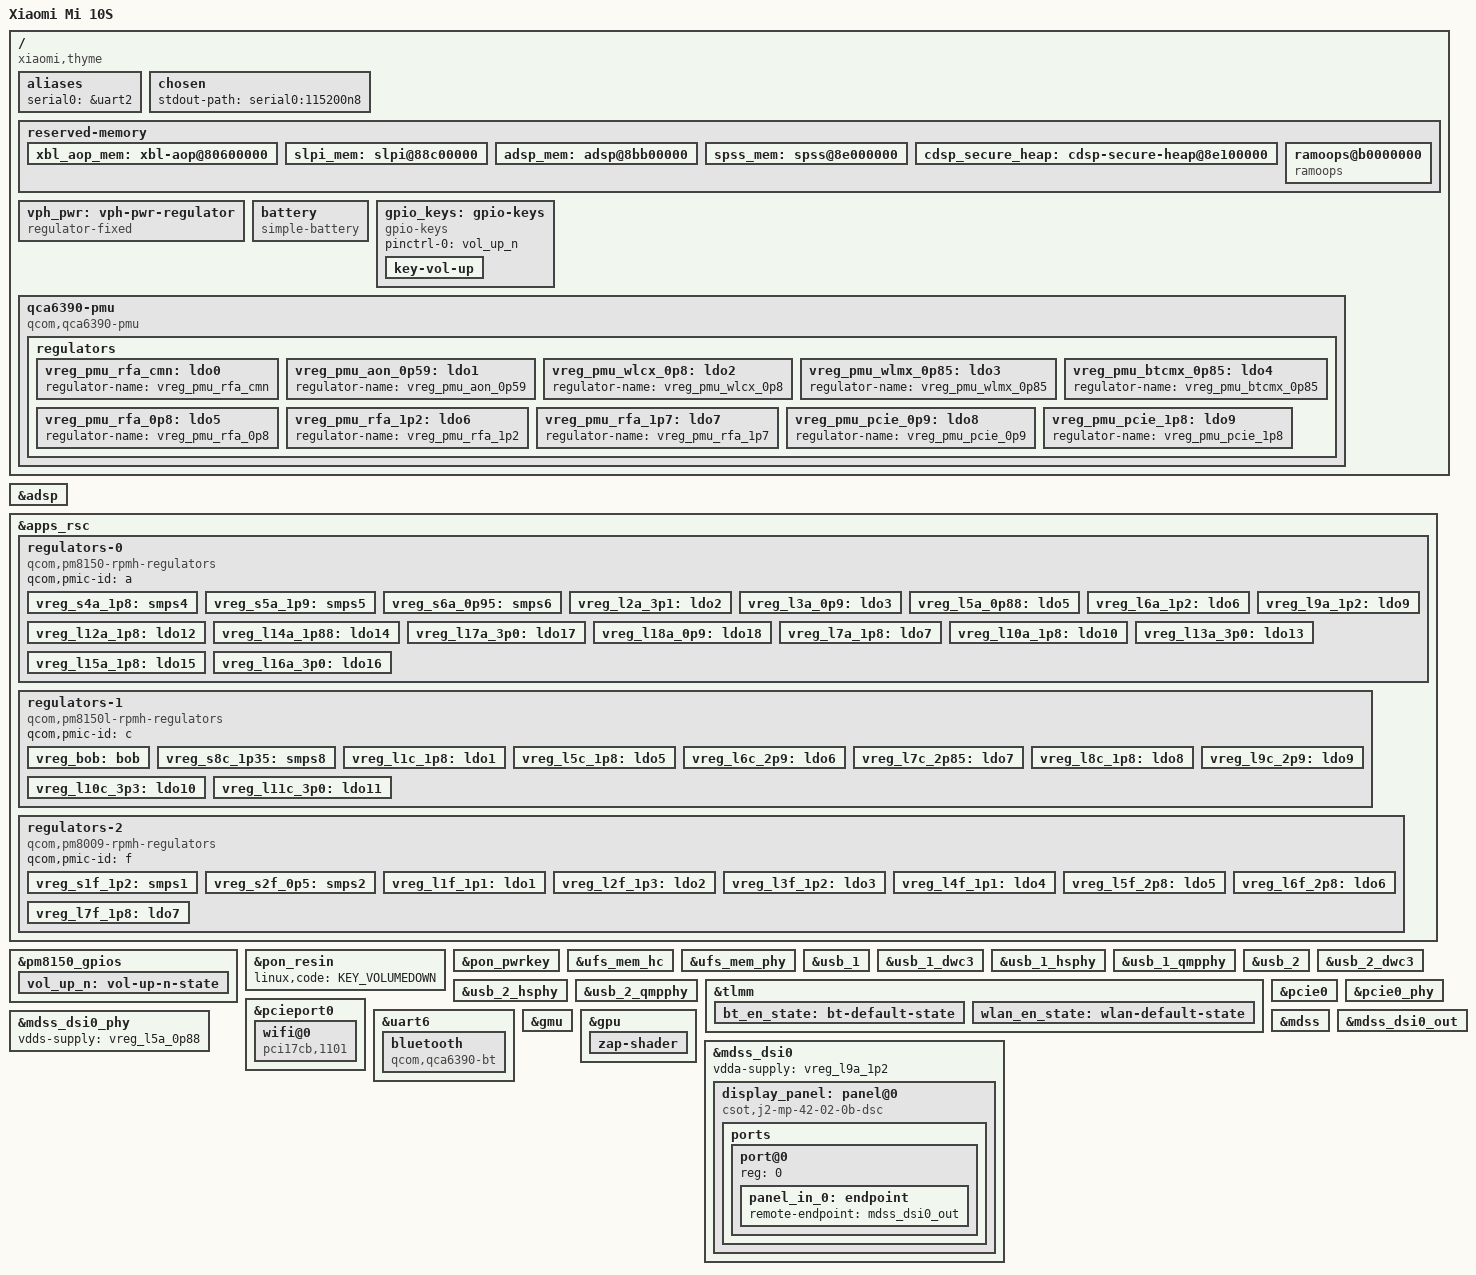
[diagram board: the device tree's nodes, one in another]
// SPDX-License-Identifier: BSD-3-Clause
/*
 * Xiaomi Mi 10S (thyme) — SM8250 (Kona v2.1)
 *
 * 基于 Linux 6.13 sm8250 平台骨架，独立构建。
 * 硬件事实来源：官方 4.19.157-perf 反编译树 dts-reference/thyme-official-full.dts。
 * 组织方式参照 sm8250-xiaomi-elish-common.dtsi（同为 Xiaomi SM8250）。
 *
 * 首批迁移：基础平台 / reserved-memory / PMIC / UFS / USB / 基础 GPIO。
 * 后续批次：PCIe(Wi-Fi/BT) / DPU·DSI / GPU / Audio / Touch / Charging / Sensors。
 */

/dts-v1/;

#include <dt-bindings/arm/qcom,ids.h>
#include <dt-bindings/gpio/gpio.h>
#include <dt-bindings/input/input.h>
#include <dt-bindings/leds/common.h>
#include <dt-bindings/phy/phy.h>
#include <dt-bindings/regulator/qcom,rpmh-regulator.h>
#include <dt-bindings/usb/pd.h>
#include "sm8250.dtsi"
#include "pm8150.dtsi"
#include "pm8150b.dtsi"
#include "pm8150l.dtsi"
#include "pm8009.dtsi"

/*
 * thyme 与 elish 同为 Xiaomi SM8250，reserved-memory 布局一致，
 * 且均与上游 sm8250.dtsi 默认值不同，故删除后按官方 4.19 值重定义。
 */
/delete-node/ &adsp_mem;
/delete-node/ &cdsp_secure_heap;
/delete-node/ &slpi_mem;
/delete-node/ &spss_mem;
/delete-node/ &xbl_aop_mem;

/ {
	model = "Xiaomi Mi 10S";
	compatible = "xiaomi,thyme", "qcom,sm8250";
	chassis-type = "handset";

	/* bootloader 选板依据（官方 4.19：msm-id 0x164/board-id 0x2d） */
	qcom,msm-id = <QCOM_ID_SM8250 0x20001>; /* SM8250 v2.1 */
	qcom,board-id = <45 0>;

	aliases {
		serial0 = &uart2;
	};

	chosen {
		stdout-path = "serial0:115200n8";
	};

	/*
	 * 内存布局由 bootloader 运行时填充（官方 4.19 静态 reg 为占位 0，
	 * 6.13 sm8250.dtsi 默认 memory@80000000 同样 size=0，由 BL 填 size）。
	 * 故不在此声明 memory，直接继承 6.13 基座的 bootloader-fill 语义。
	 */

	reserved-memory {
		xbl_aop_mem: xbl-aop@80600000 {
			reg = <0x0 0x80600000 0x0 0x260000>;
			no-map;
		};

		slpi_mem: slpi@88c00000 {
			reg = <0x0 0x88c00000 0x0 0x2f00000>;
			no-map;
		};

		adsp_mem: adsp@8bb00000 {
			reg = <0x0 0x8bb00000 0x0 0x2500000>;
			no-map;
		};

		spss_mem: spss@8e000000 {
			reg = <0x0 0x8e000000 0x0 0x100000>;
			no-map;
		};

		cdsp_secure_heap: cdsp-secure-heap@8e100000 {
			reg = <0x0 0x8e100000 0x0 0x4600000>;
			no-map;
		};

		ramoops@b0000000 {
			compatible = "ramoops";
			reg = <0x0 0xb0000000 0x0 0x400000>;
			record-size = <0x1000>;
			console-size = <0x200000>;
			ecc-size = <16>;
			no-map;
		};
	};

	vph_pwr: vph-pwr-regulator {
		compatible = "regulator-fixed";
		regulator-name = "vph_pwr";
		regulator-min-microvolt = <3700000>;
		regulator-max-microvolt = <3700000>;
	};

	/*
	 * 官方 4.19 throma j2nvtbm4n/j2gybm4n，4780mAh 双电芯六针。
	 * 电量计为高通 fg-gen4（6.13 无 driver），Capacity 值先落 simple-battery。
	 */
	battery: battery {
		compatible = "simple-battery";
		charge-full-design-microamp-hours = <4780000>;
		voltage-min-design-microvolt = <3870000>;
		energy-full-design-microwatt-hours = <18400000>;
	};

	gpio_keys: gpio-keys {
		compatible = "gpio-keys";

		pinctrl-names = "default";
		pinctrl-0 = <&vol_up_n>;

		key-vol-up {
			label = "Volume Up";
			gpios = <&pm8150_gpios 6 GPIO_ACTIVE_LOW>;
			linux,code = <KEY_VOLUMEUP>;
			debounce-interval = <15>;
			linux,can-disable;
			wakeup-source;
		};
	};

	/*
	 * QCA6390 Wi-Fi/Bluetooth 电源管理单元。
	 * 官方 4.19 cnss 五路供电(aon/dig/io/rfa1/rfa2) 在此改为 mainline pmu binding。
	 */
	qca6390-pmu {
		compatible = "qcom,qca6390-pmu";

		pinctrl-names = "default";
		pinctrl-0 = <&bt_en_state>, <&wlan_en_state>;

		vddaon-supply = <&vreg_s6a_0p95>;
		vddpmu-supply = <&vreg_s6a_0p95>;
		vddrfa0p95-supply = <&vreg_s6a_0p95>;
		vddrfa1p3-supply = <&vreg_s8c_1p35>;
		vddrfa1p9-supply = <&vreg_s5a_1p9>;
		vddpcie1p3-supply = <&vreg_s8c_1p35>;
		vddpcie1p9-supply = <&vreg_s5a_1p9>;
		vddio-supply = <&vreg_s4a_1p8>;

		wlan-enable-gpios = <&tlmm 20 GPIO_ACTIVE_HIGH>;
		bt-enable-gpios = <&tlmm 21 GPIO_ACTIVE_HIGH>;

		regulators {
			vreg_pmu_rfa_cmn: ldo0 {
				regulator-name = "vreg_pmu_rfa_cmn";
			};

			vreg_pmu_aon_0p59: ldo1 {
				regulator-name = "vreg_pmu_aon_0p59";
			};

			vreg_pmu_wlcx_0p8: ldo2 {
				regulator-name = "vreg_pmu_wlcx_0p8";
			};

			vreg_pmu_wlmx_0p85: ldo3 {
				regulator-name = "vreg_pmu_wlmx_0p85";
			};

			vreg_pmu_btcmx_0p85: ldo4 {
				regulator-name = "vreg_pmu_btcmx_0p85";
			};

			vreg_pmu_rfa_0p8: ldo5 {
				regulator-name = "vreg_pmu_rfa_0p8";
			};

			vreg_pmu_rfa_1p2: ldo6 {
				regulator-name = "vreg_pmu_rfa_1p2";
			};

			vreg_pmu_rfa_1p7: ldo7 {
				regulator-name = "vreg_pmu_rfa_1p7";
			};

			vreg_pmu_pcie_0p9: ldo8 {
				regulator-name = "vreg_pmu_pcie_0p9";
			};

			vreg_pmu_pcie_1p8: ldo9 {
				regulator-name = "vreg_pmu_pcie_1p8";
			};
		};
	};
};

&adsp {
	status = "okay";
	firmware-name = "qcom/sm8250/xiaomi/thyme/adsp.mbn";
};

&apps_rsc {
	regulators-0 {
		compatible = "qcom,pm8150-rpmh-regulators";
		qcom,pmic-id = "a";

		vreg_s4a_1p8: smps4 {
			regulator-name = "vreg_s4a_1p8";
			regulator-min-microvolt = <1800000>;
			regulator-max-microvolt = <1920000>;
			regulator-initial-mode = <RPMH_REGULATOR_MODE_HPM>;
		};

		vreg_s5a_1p9: smps5 {
			regulator-name = "vreg_s5a_1p9";
			regulator-min-microvolt = <1824000>;
			regulator-max-microvolt = <2040000>;
			regulator-initial-mode = <RPMH_REGULATOR_MODE_HPM>;
		};

		vreg_s6a_0p95: smps6 {
			regulator-name = "vreg_s6a_0p95";
			regulator-min-microvolt = <600000>;
			regulator-max-microvolt = <1128000>;
			regulator-initial-mode = <RPMH_REGULATOR_MODE_HPM>;
		};

		vreg_l2a_3p1: ldo2 {
			regulator-name = "vreg_l2a_3p1";
			regulator-min-microvolt = <3072000>;
			regulator-max-microvolt = <3072000>;
			regulator-initial-mode = <RPMH_REGULATOR_MODE_HPM>;
		};

		vreg_l3a_0p9: ldo3 {
			regulator-name = "vreg_l3a_0p9";
			regulator-min-microvolt = <928000>;
			regulator-max-microvolt = <932000>;
			regulator-initial-mode = <RPMH_REGULATOR_MODE_HPM>;
		};

		vreg_l5a_0p88: ldo5 {
			regulator-name = "vreg_l5a_0p88";
			regulator-min-microvolt = <880000>;
			regulator-max-microvolt = <880000>;
			regulator-initial-mode = <RPMH_REGULATOR_MODE_HPM>;
		};

		vreg_l6a_1p2: ldo6 {
			regulator-name = "vreg_l6a_1p2";
			regulator-min-microvolt = <1200000>;
			regulator-max-microvolt = <1200000>;
			regulator-initial-mode = <RPMH_REGULATOR_MODE_HPM>;
		};

		vreg_l9a_1p2: ldo9 {
			regulator-name = "vreg_l9a_1p2";
			regulator-min-microvolt = <1200000>;
			regulator-max-microvolt = <1200000>;
			regulator-initial-mode = <RPMH_REGULATOR_MODE_HPM>;
		};

		vreg_l12a_1p8: ldo12 {
			regulator-name = "vreg_l12a_1p8";
			regulator-min-microvolt = <1800000>;
			regulator-max-microvolt = <1800000>;
			regulator-initial-mode = <RPMH_REGULATOR_MODE_HPM>;
		};

		vreg_l14a_1p88: ldo14 {
			regulator-name = "vreg_l14a_1p88";
			regulator-min-microvolt = <1800000>;
			regulator-max-microvolt = <1880000>;
			regulator-initial-mode = <RPMH_REGULATOR_MODE_HPM>;
		};

		vreg_l17a_3p0: ldo17 {
			regulator-name = "vreg_l17a_3p0";
			regulator-min-microvolt = <2496000>;
			regulator-max-microvolt = <3008000>;
			regulator-initial-mode = <RPMH_REGULATOR_MODE_HPM>;
		};

		vreg_l18a_0p9: ldo18 {
			regulator-name = "vreg_l18a_0p9";
			regulator-min-microvolt = <912000>;
			regulator-max-microvolt = <912000>;
			regulator-initial-mode = <RPMH_REGULATOR_MODE_HPM>;
		};

		vreg_l7a_1p8: ldo7 {
			regulator-name = "vreg_l7a_1p8";
			regulator-min-microvolt = <1704000>;
			regulator-max-microvolt = <1800000>;
			regulator-initial-mode = <RPMH_REGULATOR_MODE_HPM>;
		};

		vreg_l10a_1p8: ldo10 {
			regulator-name = "vreg_l10a_1p8";
			regulator-min-microvolt = <1800000>;
			regulator-max-microvolt = <2960000>;
			regulator-initial-mode = <RPMH_REGULATOR_MODE_HPM>;
		};

		vreg_l13a_3p0: ldo13 {
			regulator-name = "vreg_l13a_3p0";
			regulator-min-microvolt = <3008000>;
			regulator-max-microvolt = <3008000>;
			regulator-initial-mode = <RPMH_REGULATOR_MODE_HPM>;
		};

		vreg_l15a_1p8: ldo15 {
			regulator-name = "vreg_l15a_1p8";
			regulator-min-microvolt = <1800000>;
			regulator-max-microvolt = <1800000>;
			regulator-initial-mode = <RPMH_REGULATOR_MODE_HPM>;
		};

		vreg_l16a_3p0: ldo16 {
			regulator-name = "vreg_l16a_3p0";
			regulator-min-microvolt = <3024000>;
			regulator-max-microvolt = <3304000>;
			regulator-initial-mode = <RPMH_REGULATOR_MODE_HPM>;
		};
	};

	regulators-1 {
		compatible = "qcom,pm8150l-rpmh-regulators";
		qcom,pmic-id = "c";

		vreg_bob: bob {
			regulator-name = "vreg_bob";
			regulator-min-microvolt = <3008000>;
			regulator-max-microvolt = <3960000>;
			regulator-initial-mode = <RPMH_REGULATOR_MODE_AUTO>;
		};

		vreg_s8c_1p35: smps8 {
			regulator-name = "vreg_s8c_1p35";
			regulator-min-microvolt = <1200000>;
			regulator-max-microvolt = <1400000>;
			regulator-initial-mode = <RPMH_REGULATOR_MODE_HPM>;
		};

		vreg_l1c_1p8: ldo1 {
			regulator-name = "vreg_l1c_1p8";
			regulator-min-microvolt = <1800000>;
			regulator-max-microvolt = <1800000>;
			regulator-initial-mode = <RPMH_REGULATOR_MODE_HPM>;
		};

		vreg_l5c_1p8: ldo5 {
			regulator-name = "vreg_l5c_1p8";
			regulator-min-microvolt = <1800000>;
			regulator-max-microvolt = <2800000>;
			regulator-initial-mode = <RPMH_REGULATOR_MODE_HPM>;
		};

		vreg_l6c_2p9: ldo6 {
			regulator-name = "vreg_l6c_2p9";
			regulator-min-microvolt = <1800000>;
			regulator-max-microvolt = <2960000>;
			regulator-initial-mode = <RPMH_REGULATOR_MODE_HPM>;
		};

		vreg_l7c_2p85: ldo7 {
			regulator-name = "vreg_l7c_2p85";
			regulator-min-microvolt = <2856000>;
			regulator-max-microvolt = <3104000>;
			regulator-initial-mode = <RPMH_REGULATOR_MODE_HPM>;
		};

		vreg_l8c_1p8: ldo8 {
			regulator-name = "vreg_l8c_1p8";
			regulator-min-microvolt = <1800000>;
			regulator-max-microvolt = <1800000>;
			regulator-initial-mode = <RPMH_REGULATOR_MODE_HPM>;
		};

		vreg_l9c_2p9: ldo9 {
			regulator-name = "vreg_l9c_2p9";
			regulator-min-microvolt = <2704000>;
			regulator-max-microvolt = <2960000>;
			regulator-initial-mode = <RPMH_REGULATOR_MODE_HPM>;
		};

		vreg_l10c_3p3: ldo10 {
			regulator-name = "vreg_l10c_3p3";
			regulator-min-microvolt = <3000000>;
			regulator-max-microvolt = <3312000>;
			regulator-initial-mode = <RPMH_REGULATOR_MODE_HPM>;
		};

		vreg_l11c_3p0: ldo11 {
			regulator-name = "vreg_l11c_3p0";
			regulator-min-microvolt = <3000000>;
			regulator-max-microvolt = <3312000>;
			regulator-initial-mode = <RPMH_REGULATOR_MODE_HPM>;
		};
	};

	regulators-2 {
		compatible = "qcom,pm8009-rpmh-regulators";
		qcom,pmic-id = "f";

		vreg_s1f_1p2: smps1 {
			regulator-name = "vreg_s1f_1p2";
			regulator-min-microvolt = <1200000>;
			regulator-max-microvolt = <1300000>;
			regulator-initial-mode = <RPMH_REGULATOR_MODE_HPM>;
		};

		vreg_s2f_0p5: smps2 {
			regulator-name = "vreg_s2f_0p5";
			regulator-min-microvolt = <512000>;
			regulator-max-microvolt = <1100000>;
			regulator-initial-mode = <RPMH_REGULATOR_MODE_HPM>;
		};

		vreg_l1f_1p1: ldo1 {
			regulator-name = "vreg_l1f_1p1";
			regulator-min-microvolt = <1104000>;
			regulator-max-microvolt = <1104000>;
			regulator-initial-mode = <RPMH_REGULATOR_MODE_HPM>;
		};

		vreg_l2f_1p3: ldo2 {
			regulator-name = "vreg_l2f_1p3";
			regulator-min-microvolt = <1056000>;
			regulator-max-microvolt = <1200000>;
			regulator-initial-mode = <RPMH_REGULATOR_MODE_HPM>;
		};

		vreg_l3f_1p2: ldo3 {
			regulator-name = "vreg_l3f_1p2";
			regulator-min-microvolt = <1056000>;
			regulator-max-microvolt = <1200000>;
			regulator-initial-mode = <RPMH_REGULATOR_MODE_HPM>;
		};

		vreg_l4f_1p1: ldo4 {
			regulator-name = "vreg_l4f_1p1";
			regulator-min-microvolt = <1104000>;
			regulator-max-microvolt = <1104000>;
			regulator-initial-mode = <RPMH_REGULATOR_MODE_HPM>;
		};

		vreg_l5f_2p8: ldo5 {
			regulator-name = "vreg_l5f_2p8";
			regulator-min-microvolt = <2800000>;
			regulator-max-microvolt = <3000000>;
			regulator-initial-mode = <RPMH_REGULATOR_MODE_HPM>;
		};

		vreg_l6f_2p8: ldo6 {
			regulator-name = "vreg_l6f_2p8";
			regulator-min-microvolt = <2800000>;
			regulator-max-microvolt = <3000000>;
			regulator-initial-mode = <RPMH_REGULATOR_MODE_HPM>;
		};

		vreg_l7f_1p8: ldo7 {
			regulator-name = "vreg_l7f_1p8";
			regulator-min-microvolt = <1800000>;
			regulator-max-microvolt = <1800000>;
			regulator-initial-mode = <RPMH_REGULATOR_MODE_HPM>;
		};
	};
};

&pm8150_gpios {
	vol_up_n: vol-up-n-state {
		pins = "gpio6";
		function = "normal";
		input-enable;
		bias-pull-up;
		power-source = <1>;
	};
};

&pon_resin {
	status = "okay";
	linux,code = <KEY_VOLUMEDOWN>;
};

&pon_pwrkey {
	status = "okay";
};

&ufs_mem_hc {
	vcc-supply = <&vreg_l17a_3p0>;
	vcc-max-microamp = <800000>;
	vccq-supply = <&vreg_l6a_1p2>;
	vccq-max-microamp = <800000>;
	vccq2-supply = <&vreg_s4a_1p8>;
	vccq2-max-microamp = <800000>;
	status = "okay";
};

&ufs_mem_phy {
	vdda-phy-supply = <&vreg_l5a_0p88>;
	vdda-pll-supply = <&vreg_l9a_1p2>;
	status = "okay";
};

&usb_1 {
	status = "okay";
};

&usb_1_dwc3 {
	dr_mode = "otg";
	/* 官方 4.19 thyme usb0 = USB 2.0 only */
	maximum-speed = "high-speed";
	phys = <&usb_1_hsphy>;
	phy-names = "usb2-phy";
};

&usb_1_hsphy {
	status = "okay";

	vdda-pll-supply = <&vreg_l5a_0p88>;
	vdda33-supply = <&vreg_l2a_3p1>;
	vdda18-supply = <&vreg_l12a_1p8>;
};

/* usb_1_qmpphy（combo DP phy）供 DP 视频输出，USB 数据仍走 HS */
&usb_1_qmpphy {
	status = "okay";

	vdda-phy-supply = <&vreg_l9a_1p2>;
	vdda-pll-supply = <&vreg_l18a_0p9>;
};

&usb_2 {
	status = "okay";
};

&usb_2_dwc3 {
	dr_mode = "host";
	/* 官方 4.19 thyme usb1 = USB 3.0 super-speed */
	maximum-speed = "super-speed";
};

&usb_2_hsphy {
	status = "okay";

	vdda-pll-supply = <&vreg_l5a_0p88>;
	vdda33-supply = <&vreg_l2a_3p1>;
	vdda18-supply = <&vreg_l12a_1p8>;
};

&usb_2_qmpphy {
	status = "okay";

	vdda-phy-supply = <&vreg_l9a_1p2>;
	vdda-pll-supply = <&vreg_l18a_0p9>;
};
&tlmm {
	bt_en_state: bt-default-state {
		pins = "gpio21";
		function = "gpio";
		drive-strength = <16>;
		output-low;
		bias-pull-up;
	};

	wlan_en_state: wlan-default-state {
		pins = "gpio20";
		function = "gpio";
		drive-strength = <16>;
		output-low;
		bias-pull-up;
	};
};

&pcie0 {
	status = "okay";
};

&pcie0_phy {
	vdda-phy-supply = <&vreg_l5a_0p88>;
	vdda-pll-supply = <&vreg_l9a_1p2>;
	status = "okay";
};

&pcieport0 {
	wifi@0 {
		compatible = "pci17cb,1101";
		reg = <0x10000 0x0 0x0 0x0 0x0>;

		vddrfacmn-supply = <&vreg_pmu_rfa_cmn>;
		vddaon-supply = <&vreg_pmu_aon_0p59>;
		vddwlcx-supply = <&vreg_pmu_wlcx_0p8>;
		vddwlmx-supply = <&vreg_pmu_wlmx_0p85>;
		vddrfa0p8-supply = <&vreg_pmu_rfa_0p8>;
		vddrfa1p2-supply = <&vreg_pmu_rfa_1p2>;
		vddrfa1p7-supply = <&vreg_pmu_rfa_1p7>;
		vddpcie0p9-supply = <&vreg_pmu_pcie_0p9>;
		vddpcie1p8-supply = <&vreg_pmu_pcie_1p8>;

		/* calibration-variant 待从 thyme 实机 firmware 确认（elish 用 "Xiaomi_Pad_5Pro"） */
	};
};

&uart6 {
	status = "okay";

	bluetooth {
		compatible = "qcom,qca6390-bt";

		vddrfacmn-supply = <&vreg_pmu_rfa_cmn>;
		vddaon-supply = <&vreg_pmu_aon_0p59>;
		vddbtcmx-supply = <&vreg_pmu_btcmx_0p85>;
		vddrfa0p8-supply = <&vreg_pmu_rfa_0p8>;
		vddrfa1p2-supply = <&vreg_pmu_rfa_1p2>;
		vddrfa1p7-supply = <&vreg_pmu_rfa_1p7>;
	};
};

&gmu {
	status = "okay";
};

&gpu {
	status = "okay";

	zap-shader {
		memory-region = <&gpu_mem>;
		firmware-name = "qcom/sm8250/xiaomi/thyme/a650_zap.mbn";
	};
};

&mdss {
	status = "okay";
};

&mdss_dsi0 {
	vdda-supply = <&vreg_l9a_1p2>;
	status = "okay";

	display_panel: panel@0 {
		reg = <0>;
		/*
		 * csot,j2-mp-42-02-0b-dsc：1080×2340 + DSC，6.67"。
		 * 该 panel driver 在 7.2(umi) 存在，但 6.13 缺失，需 backport。
		 * dtbs_check 会因 compatible 未登记而告警，属预期。
		 */
		compatible = "csot,j2-mp-42-02-0b-dsc";
		vddio-supply = <&vreg_l14a_1p88>;
		reset-gpios = <&tlmm 12 GPIO_ACTIVE_LOW>;

		status = "okay";

		ports {
			#address-cells = <1>;
			#size-cells = <0>;

			port@0 {
				reg = <0>;

				panel_in_0: endpoint {
					remote-endpoint = <&mdss_dsi0_out>;
				};
			};
		};
	};
};

&mdss_dsi0_out {
	data-lanes = <0 1 2 3>;
	remote-endpoint = <&panel_in_0>;
};

&mdss_dsi0_phy {
	vdds-supply = <&vreg_l5a_0p88>;
	status = "okay";
};
